VERSION ""

NS_ :

BS_:

BU_: TTC_580 TTC32

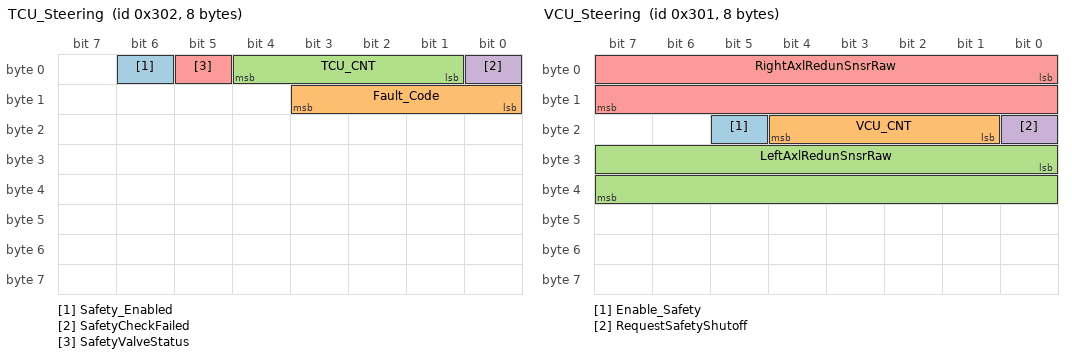
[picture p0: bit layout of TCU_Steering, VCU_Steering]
BO_ 770 TCU_Steering: 8 Vector__XXX
 SG_ Safety_Enabled : 6|1@1+ (1,0) [0|1] "" Vector__XXX
 SG_ Fault_Code : 8|4@1+ (1,0) [0|15] "" Vector__XXX
 SG_ TCU_CNT : 1|4@1+ (1,0) [0|15] "" Vector__XXX
 SG_ SafetyCheckFailed : 0|1@1+ (1,0) [0|1] "" Vector__XXX
 SG_ SafetyValveStatus : 5|1@1+ (1,0) [0|1] "" Vector__XXX

BO_ 769 VCU_Steering: 8 TTC32
 SG_ Enable_Safety : 21|1@1+ (1,0) [0|1] "" Vector__XXX
 SG_ VCU_CNT : 17|4@1+ (1,0) [0|15] "" Vector__XXX
 SG_ LeftAxlRedunSnsrRaw : 24|16@1+ (1,0) [0|65535] "mV" Vector__XXX
 SG_ RequestSafetyShutoff : 16|1@1+ (1,0) [0|1] ""  TTC_580
 SG_ RightAxlRedunSnsrRaw : 0|16@1+ (1,0) [0|65535] "mV"  TTC_580

BA_DEF_  "BusType" STRING ;
BA_DEF_DEF_  "BusType" "CAN";
